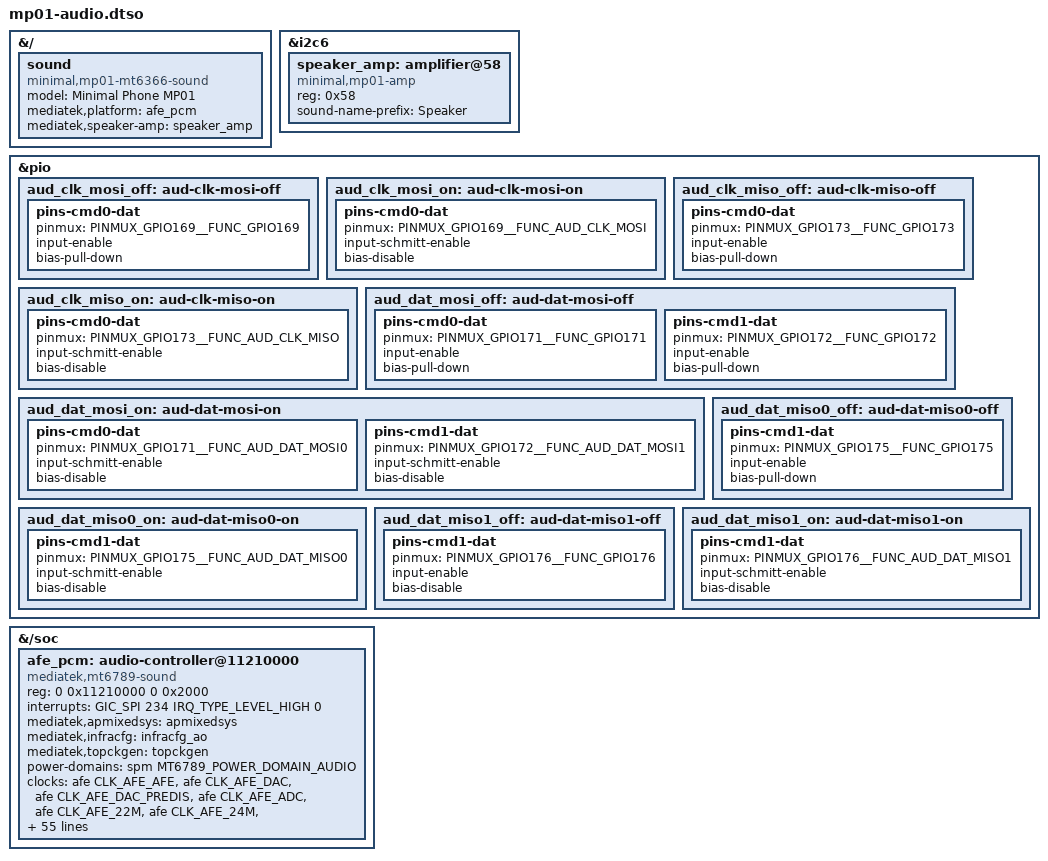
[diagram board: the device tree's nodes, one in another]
// SPDX-License-Identifier: GPL-2.0-only OR MIT
/*
 * The MP01's sound card for the audio modules in mp01-kernel-modules: the
 * MT6789 AFE, the MT6366 codec the board DT describes and the OCA72390
 * speaker amplifier on I2C6, bound by the Zinwa Q25's machine driver. The
 * AFE and card compatibles are not upstream, so they stay out of the board
 * DT; the kernel package merges this into mt6789-minimal-mp01-vendor.dtb.
 * The AFE node and its pin states are the Q25's: the MP01 factory DT has
 * the same ten AUD pin states.
 */

/dts-v1/;
/plugin/;

#include <dt-bindings/clock/mediatek,mt6789-clk.h>
#include <dt-bindings/interrupt-controller/arm-gic.h>
#include <dt-bindings/interrupt-controller/irq.h>
#include <dt-bindings/pinctrl/mediatek,mt6789-pinfunc.h>
#include <dt-bindings/power/mediatek,mt6789-power.h>

&{/} {
	sound {
		compatible = "minimal,mp01-mt6366-sound";
		model = "Minimal Phone MP01";
		mediatek,platform = <&afe_pcm>;
		mediatek,speaker-amp = <&speaker_amp>;
	};
};

/* Speaker amplifier: OCA72390, no enable or reset line. */
&i2c6 {
	speaker_amp: amplifier@58 {
		compatible = "minimal,mp01-amp", "ocs,oca72390";
		reg = <0x58>;
		#sound-dai-cells = <0>;
		sound-name-prefix = "Speaker";
	};
};

&pio {
	aud_clk_mosi_off: aud-clk-mosi-off {
		pins-cmd0-dat {
			pinmux = <PINMUX_GPIO169__FUNC_GPIO169>;
			input-enable;
			bias-pull-down;
		};
	};

	aud_clk_mosi_on: aud-clk-mosi-on {
		pins-cmd0-dat {
			pinmux = <PINMUX_GPIO169__FUNC_AUD_CLK_MOSI>;
			input-schmitt-enable;
			bias-disable;
		};
	};

	aud_clk_miso_off: aud-clk-miso-off {
		pins-cmd0-dat {
			pinmux = <PINMUX_GPIO173__FUNC_GPIO173>;
			input-enable;
			bias-pull-down;
		};
	};

	aud_clk_miso_on: aud-clk-miso-on {
		pins-cmd0-dat {
			pinmux = <PINMUX_GPIO173__FUNC_AUD_CLK_MISO>;
			input-schmitt-enable;
			bias-disable;
		};
	};

	aud_dat_mosi_off: aud-dat-mosi-off {
		pins-cmd0-dat {
			pinmux = <PINMUX_GPIO171__FUNC_GPIO171>;
			input-enable;
			bias-pull-down;
		};

		pins-cmd1-dat {
			pinmux = <PINMUX_GPIO172__FUNC_GPIO172>;
			input-enable;
			bias-pull-down;
		};
	};

	aud_dat_mosi_on: aud-dat-mosi-on {
		pins-cmd0-dat {
			pinmux = <PINMUX_GPIO171__FUNC_AUD_DAT_MOSI0>;
			input-schmitt-enable;
			bias-disable;
		};

		pins-cmd1-dat {
			pinmux = <PINMUX_GPIO172__FUNC_AUD_DAT_MOSI1>;
			input-schmitt-enable;
			bias-disable;
		};
	};

	aud_dat_miso0_off: aud-dat-miso0-off {
		pins-cmd1-dat {
			pinmux = <PINMUX_GPIO175__FUNC_GPIO175>;
			input-enable;
			bias-pull-down;
		};
	};

	aud_dat_miso0_on: aud-dat-miso0-on {
		pins-cmd1-dat {
			pinmux = <PINMUX_GPIO175__FUNC_AUD_DAT_MISO0>;
			input-schmitt-enable;
			bias-disable;
		};
	};

	aud_dat_miso1_off: aud-dat-miso1-off {
		pins-cmd1-dat {
			pinmux = <PINMUX_GPIO176__FUNC_GPIO176>;
			input-enable;
			bias-disable;
		};
	};

	aud_dat_miso1_on: aud-dat-miso1-on {
		pins-cmd1-dat {
			pinmux = <PINMUX_GPIO176__FUNC_AUD_DAT_MISO1>;
			input-schmitt-enable;
			bias-disable;
		};
	};

};

&{/soc} {
	afe_pcm: audio-controller@11210000 {
		compatible = "mediatek,mt6789-sound";
		reg = <0 0x11210000 0 0x2000>;
		interrupts = <GIC_SPI 234 IRQ_TYPE_LEVEL_HIGH 0>;
		mediatek,apmixedsys = <&apmixedsys>;
		mediatek,infracfg = <&infracfg_ao>;
		mediatek,topckgen = <&topckgen>;
		power-domains = <&spm MT6789_POWER_DOMAIN_AUDIO>;
		clocks = <&afe CLK_AFE_AFE>,
			 <&afe CLK_AFE_DAC>,
			 <&afe CLK_AFE_DAC_PREDIS>,
			 <&afe CLK_AFE_ADC>,
			 <&afe CLK_AFE_22M>,
			 <&afe CLK_AFE_24M>,
			 <&afe CLK_AFE_APLL_TUNER>,
			 <&afe CLK_AFE_APLL2_TUNER>,
			 <&afe CLK_AFE_TML>,
			 <&afe CLK_AFE_NLE>,
			 <&afe CLK_AFE_DAC_HIRES>,
			 <&afe CLK_AFE_ADC_HIRES>,
			 <&afe CLK_AFE_ADC_HIRES_TML>,
			 <&afe CLK_AFE_I2S1_BCLK>,
			 <&afe CLK_AFE_I2S2_BCLK>,
			 <&afe CLK_AFE_I2S3_BCLK>,
			 <&afe CLK_AFE_I2S4_BCLK>,
			 <&afe CLK_AFE_GENERAL3_ASRC>,
			 <&afe CLK_AFE_CONNSYS_I2S_ASRC>,
			 <&afe CLK_AFE_GENERAL1_ASRC>,
			 <&afe CLK_AFE_GENERAL2_ASRC>,
			 <&infracfg_ao CLK_IFRAO_AUDIO>,
			 <&infracfg_ao CLK_IFRAO_AUDIO_26M_BCLK>,
			 <&apmixedsys CLK_APMIXED_APLL1>,
			 <&apmixedsys CLK_APMIXED_APLL2>,
			 <&topckgen CLK_TOP_AUDIO_SEL>,
			 <&topckgen CLK_TOP_AUD_INTBUS_SEL>,
			 <&topckgen CLK_TOP_MAINPLL_D4_D4>,
			 <&topckgen CLK_TOP_AUD_1_SEL>,
			 <&topckgen CLK_TOP_APLL1>,
			 <&topckgen CLK_TOP_AUD_2_SEL>,
			 <&topckgen CLK_TOP_APLL2>,
			 <&topckgen CLK_TOP_AUD_ENGEN1_SEL>,
			 <&topckgen CLK_TOP_APLL1_D4>,
			 <&topckgen CLK_TOP_APLL1_D8>,
			 <&topckgen CLK_TOP_AUD_ENGEN2_SEL>,
			 <&topckgen CLK_TOP_APLL2_D4>,
			 <&topckgen CLK_TOP_APLL2_D8>,
			 <&topckgen CLK_TOP_APLL_I2S0_MCK_SEL>,
			 <&topckgen CLK_TOP_APLL_I2S1_MCK_SEL>,
			 <&topckgen CLK_TOP_APLL_I2S2_MCK_SEL>,
			 <&topckgen CLK_TOP_APLL_I2S3_MCK_SEL>,
			 <&topckgen CLK_TOP_APLL_I2S4_MCK_SEL>,
			 <&topckgen CLK_TOP_APLL_I2S5_MCK_SEL>,
			 <&topckgen CLK_TOP_APLL12_CK_DIV0>,
			 <&topckgen CLK_TOP_APLL12_CK_DIV1>,
			 <&topckgen CLK_TOP_APLL12_CK_DIV2>,
			 <&topckgen CLK_TOP_APLL12_CK_DIV3>,
			 <&topckgen CLK_TOP_APLL12_CK_DIV4>,
			 <&topckgen CLK_TOP_APLL12_CK_DIVB>,
			 <&topckgen CLK_TOP_APLL12_CK_DIV5>,
			 <&topckgen CLK_TOP_AUDIO_H_SEL>,
			 <&topckgen CLK_TOP_TCK_26M_MX9>;
		clock-names = "aud_afe_clk", "aud_dac_clk", "aud_dac_predis_clk",
			      "aud_adc_clk", "aud_apll22m_clk", "aud_apll24m_clk",
			      "aud_apll1_tuner_clk", "aud_apll2_tuner_clk",
			      "aud_tml_clk", "aud_nle", "aud_dac_hires_clk",
			      "aud_adc_hires_clk", "aud_adc_hires_tml",
			      "aud_i2s1_bclk", "aud_i2s2_bclk", "aud_i2s3_bclk",
			      "aud_i2s4_bclk", "aud_general3_asrc",
			      "aud_connsys_i2s_asrc", "aud_general1_asrc",
			      "aud_general2_asrc", "aud_infra_clk",
			      "aud_infra_26m_clk", "aud_clk_apmixed_apll1",
			      "aud_clk_apmixed_apll2", "top_mux_audio",
			      "top_mux_audio_int", "top_mainpll_d4_d4",
			      "top_mux_aud_1", "top_apll1_ck", "top_mux_aud_2",
			      "top_apll2_ck", "top_mux_aud_eng1", "top_apll1_d4",
			      "top_apll1_d8", "top_mux_aud_eng2", "top_apll2_d4",
			      "top_apll2_d8", "top_i2s0_m_sel", "top_i2s1_m_sel",
			      "top_i2s2_m_sel", "top_i2s3_m_sel", "top_i2s4_m_sel",
			      "top_i2s5_m_sel", "top_apll12_div0", "top_apll12_div1",
			      "top_apll12_div2", "top_apll12_div3", "top_apll12_div4",
			      "top_apll12_divb", "top_apll12_div5", "top_mux_audio_h",
			      "top_clk26m_clk";
		pinctrl-names = "aud_clk_mosi_off", "aud_clk_mosi_on",
				"aud_clk_miso_off", "aud_clk_miso_on",
				"aud_dat_mosi_off", "aud_dat_mosi_on",
				"aud_dat_miso0_off", "aud_dat_miso0_on",
				"aud_dat_miso1_off", "aud_dat_miso1_on";
		pinctrl-0 = <&aud_clk_mosi_off>;
		pinctrl-1 = <&aud_clk_mosi_on>;
		pinctrl-2 = <&aud_clk_miso_off>;
		pinctrl-3 = <&aud_clk_miso_on>;
		pinctrl-4 = <&aud_dat_mosi_off>;
		pinctrl-5 = <&aud_dat_mosi_on>;
		pinctrl-6 = <&aud_dat_miso0_off>;
		pinctrl-7 = <&aud_dat_miso0_on>;
		pinctrl-8 = <&aud_dat_miso1_off>;
		pinctrl-9 = <&aud_dat_miso1_on>;
	};
};
